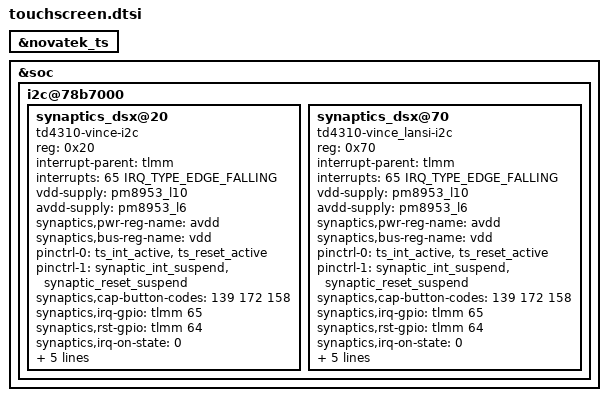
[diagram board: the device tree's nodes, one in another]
&novatek_ts {
	status = "okay";
};

&soc { 
	i2c@78b7000 { /* BLSP1 QUP3 */
		status = "okay";

		/delete-node/ synaptics@4b;
		synaptics_dsx@20 {
			compatible = "td4310-vince-i2c";
			reg = <0x20>;
			interrupt-parent = <&tlmm>;
			interrupts = <65 IRQ_TYPE_EDGE_FALLING>;
			vdd-supply = <&pm8953_l10>;
			avdd-supply = <&pm8953_l6>;
			synaptics,pwr-reg-name = "avdd";
			synaptics,bus-reg-name = "vdd";
			pinctrl-names = "pmx_ts_active", "pmx_ts_suspend";
			pinctrl-0 = <&ts_int_active &ts_reset_active>;
            pinctrl-1 = <&synaptic_int_suspend &synaptic_reset_suspend>;
			synaptics,cap-button-codes = <139 172 158>;
			synaptics,irq-gpio = <&tlmm 65 0x2008>;
			synaptics,rst-gpio = <&tlmm 64 0x2008>;
			synaptics,irq-on-state = <0>;
			synaptics,power-delay-ms = <200>;
			synaptics,reset-active-ms = <20>;
			synaptics,reset-delay-ms = <200>;
			synaptics,reset-on-state = <0>;
			synaptics,ub-i2c-addr = <0x2c>;
		};

		synaptics_dsx@70 {
			compatible = "td4310-vince_lansi-i2c";
			reg = <0x70>;
			interrupt-parent = <&tlmm>;
			interrupts = <65 IRQ_TYPE_EDGE_FALLING>;
			vdd-supply = <&pm8953_l10>;
			avdd-supply = <&pm8953_l6>;
			synaptics,pwr-reg-name = "avdd";
			synaptics,bus-reg-name = "vdd";
			pinctrl-names = "pmx_ts_active", "pmx_ts_suspend";
			pinctrl-0 = <&ts_int_active &ts_reset_active>;
            pinctrl-1 = <&synaptic_int_suspend &synaptic_reset_suspend>;
			synaptics,cap-button-codes = <139 172 158>;
			synaptics,irq-gpio = <&tlmm 65 0x2008>;
			synaptics,rst-gpio = <&tlmm 64 0x2008>;
			synaptics,irq-on-state = <0>;
			synaptics,power-delay-ms = <200>;
			synaptics,reset-active-ms = <20>;
			synaptics,reset-delay-ms = <200>;
			synaptics,reset-on-state = <0>;
			synaptics,ub-i2c-addr = <0x2c>;
		};
	};
};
